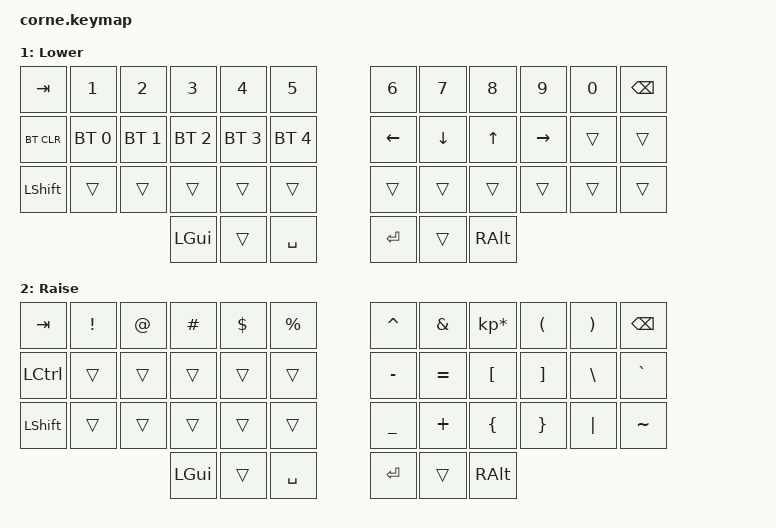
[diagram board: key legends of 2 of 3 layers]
/*
 * Copyright (c) 2020 The ZMK Contributors
 *
 * SPDX-License-Identifier: MIT
 */

#include <behaviors.dtsi>
#include <dt-bindings/zmk/keys.h>
#include <dt-bindings/zmk/bt.h>

#define HRML(k1,k2,k3,k4) &ht LCTRL k1 &ht LALT k2  &ht LGUI k3  &ht LSHFT k4
#define HRMR(k1,k2,k3,k4) &ht RCTRL k1 &ht RALT k2  &ht RGUI k3  &ht RSHFT k4

/ {
   behaviors {
        ht: hold_tap {
            label = "hold_tap";
            compatible = "zmk,behavior-hold-tap";
            #binding-cells = <2>;
            flavor = "tap-preferred";
            tapping-term-ms = <220>;
            quick-tap-ms = <150>;
            global-quick-tap;
            bindings = <&kp>, <&kp>;
        };
    };

        keymap {
                compatible = "zmk,keymap";
                default_layer {
// -----------------------------------------------------------------------------------------
// |  TAB |  Q  |  W  |  E  |  R  |  T  |   |  Y  |  U   |  I  |  O  |  P  | BKSP |
// | CTRL |  A  |  S  |  D  |  F  |  G  |   |  H  |  J   |  K  |  L  |  ;  |  '   |
// | SHFT |  Z  |  X  |  C  |  V  |  B  |   |  N  |  M   |  ,  |  .  |  /  | ESC  |
//                    | GUI | LWR | SPC |   | ENT | RSE  | ALT |
                        label = "Base";
                        bindings = <
   &kp TAB   &kp Q &kp W &kp E &kp R &kp T   &kp Y &kp U  &kp I     &kp O   &kp P    &kp BSPC
   &kp LCTRL HRML(A, S,         D,         F)  &kp G &kp H HRMR(J,        K,           L, SEMI) &kp SQT
   &kp LSHFT &kp Z &kp X &kp C &kp V &kp B   &kp N &kp M  &kp COMMA &kp DOT &kp FSLH &kp ESC
                  &kp TAB &mo 1 &kp SPACE   &kp RET &mo 2 &kp RALT
                        >;
                };
                lower_layer {
// -----------------------------------------------------------------------------------------
// |  TAB |  1  |  2  |  3  |  4  |  5  |   |  6  |  7  |  8  |  9  |  0  | BKSP |
// | BTCLR| BT1 | BT2 | BT3 | BT4 | BT5 |   | LFT | DWN |  UP | RGT |     |      |
// | SHFT |     |     |     |     |     |   |     |     |     |     |     |      |
//                    | GUI |     | SPC |   | ENT |     | ALT |
                        label = "Lower";
                        bindings = <
   &kp TAB    &kp N1       &kp N2       &kp N3       &kp N4       &kp N5         &kp N6   &kp N7   &kp N8 &kp N9    &kp N0 &kp BSPC
   &bt BT_CLR &bt BT_SEL 0 &bt BT_SEL 1 &bt BT_SEL 2 &bt BT_SEL 3 &bt BT_SEL 4   &kp LEFT &kp DOWN &kp UP &kp RIGHT &trans &trans
   &kp LSHFT  &trans       &trans       &trans       &trans       &trans         &trans   &trans   &trans &trans    &trans &trans
                          	        &kp LGUI     &trans       &kp SPACE      &kp RET  &trans   &kp RALT
                        >;
                };

                raise_layer {
// -----------------------------------------------------------------------------------------
// |  TAB |  !  |  @  |  #  |  $  |  %  |   |  ^  |  &  |  *  |  (  |  )  | BKSP |
// | CTRL |     |     |     |     |     |   |  -  |  =  |  [  |  ]  |  \  |  `   |
// | SHFT |     |     |     |     |     |   |  _  |  +  |  {  |  }  | "|" |  ~   |
//                    | GUI |     | SPC |   | ENT |     | ALT |
                        label = "Raise";
                        bindings = <
   &kp  TAB  &kp EXCL &kp AT &kp HASH &kp DLLR &kp PRCNT   &kp CARET &kp AMPS  &kp KP_MULTIPLY &kp LPAR &kp RPAR &kp BSPC
   &kp LCTRL &trans   &trans &trans   &trans   &trans      &kp MINUS &kp EQUAL &kp LBKT        &kp RBKT &kp BSLH &kp GRAVE
   &kp LSHFT &trans   &trans &trans   &trans   &trans      &kp UNDER &kp PLUS  &kp LBRC        &kp RBRC &kp PIPE &kp TILDE
                    	     &kp LGUI &trans   &kp SPACE   &kp RET   &trans    &kp RALT
                        >;
                };
        };
};
